# MCAN1_SS register map
Vendor: Texas Instruments
Peripheral module from a debugger description file (folder J7VCL).
Registers are 32-bit, read-only, reset 0x0 unless marked. A register's access mark holds for its fields unless they carry their own. Offsets are as the file gives them; lines under a group give offsets from that group; [hi:lo] are bit positions; {n}, {i} and the like mark numbered series; 'fields as' and 'values as' point back to an identical list; <NAME> marks a mode.

## MCAN1_SS
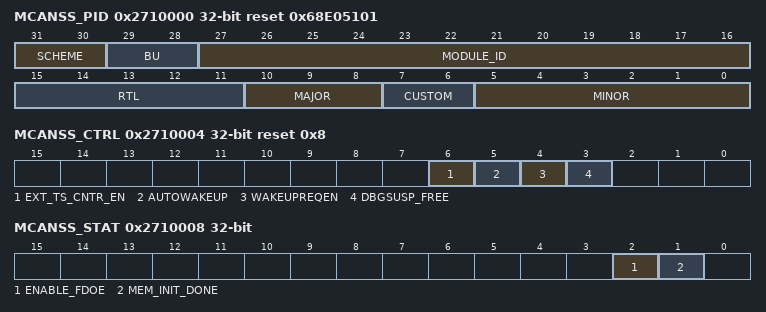
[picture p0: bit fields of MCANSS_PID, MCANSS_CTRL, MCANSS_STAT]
0x2710000 MCANSS_PID reset 0x68E05101 — Revision Register The Revision Register contains the major and minor revisions for the MCANSS.
  [31:30] SCHEME
  [29:28] BU — Business Unit (2h = Processors)
  [27:16] MODULE_ID
  [15:11] RTL — RTL Revision
  [10:8] MAJOR — Major Revision
  [7:6] CUSTOM
  [5:0] MINOR — Minor Revision
0x2710004 MCANSS_CTRL access per field reset 0x8 — Control Register The Control Register contains general control bits for the MCANSS.
  [6] EXT_TS_CNTR_EN rw — External Timestamp Counter Enable
  [5] AUTOWAKEUP rw — Automatic Wakeup Enable
  [4] WAKEUPREQEN rw — Wakeup Request Enable
  [3] DBGSUSP_FREE rw — Debug Suspend 0h = Honor debug suspend 1h = Disregard debug suspend
0x2710008 MCANSS_STAT (reset mask 0xFFFFFFFB) — Status Register The Status Register provides general status bits for the MCANSS.
  [2] ENABLE_FDOE — Enable FD (Flexible Data-Rate) Configuration Reflects the value of mcanss_enable_fdoe configuration port, -h = mcanss_enable_fdoe.
  [1] MEM_INIT_DONE — Memory Initialization 0h = Memory initialization is in progress 1h = Memory intialization done
0x271000C MCANSS_ICS access per field — Interrupt Clear Shadow Register Write 1h to clear interrupt bits.
  [0] EXT_TS_CNTR_OVFL wo — External Timestamp Counter Overflow Interrupt Status Write 1h to clear bits.
0x2710010 MCANSS_IRS access not given — Interrupt Raw Status Register Write 1h to set interrupt bits.
  [0] EXT_TS_CNTR_OVFL — External Timestamp Counter Overflow Interrupt Status Write 1h to set bits. (access RW1S)
0x2710014 MCANSS_IECS access not given — Interrupt Enable Clear Shadow Register Write 1h to clear interrupt enable bits.
  [0] EXT_TS_CNTR_OVFL — External Timestamp Counter Overflow Interrupt Write 1h to clear bits. (access W1C)
0x2710018 MCANSS_IE access not given — Interrupt Enable Register Write 1h to set interrupt bits.
  [0] EXT_TS_CNTR_OVFL — External Timestamp Counter Overflow Interrupt Write 1h to set bits. (access RW1S)
0x271001C MCANSS_IES — Interrupt Enable Status Register Read enabled interrupts.
  [0] EXT_TS_CNTR_OVFL — External Timestamp Counter Overflow Interrupt
0x2710020 MCANSS_EOI access per field — End Of Interrupt (EOI) Register The EOI register is used to re-trigger the pulse interrupt signal to ensure that any nested interrupt events are serviced. The software interrupt handler must write to the EOI register at the end of the current interrupt processing routine, so that new events can re-trigger the pulse interrupt signal again. For level interrupt signals the EOI register is not functional and must not be used.
  [7:0] EOI wo — End Of Interrupt Write with bit position of the targeted interrupt (example: external timestamp is bit 0). Upon write, level interrupt will clear and if unserviced interrupt counter &gt; 1h will issue another pulse interrupt. 0h = EOI value for external timestamp interrupt 1h = EOI value for mcan[0] interrupt 2h = EOI value for mcan[1] interrupt
0x2710024 MCANSS_EXT_TS_PRESCALER access per field — External Timestamp Prescaler Register
  [23:0] PRESCALER rw — External Timestamp Prescaler Reload Value External timestamp count rate is host clock rate divided by this value with one exception - a value of 0h has the same effect as 1h.
0x2710028 MCANSS_EXT_TS_UNSERVICED_INTR_CNTR — External Timestamp Unserviced Interrupts Counter Register
  [4:0] EXT_TS_INTR_CNTR — Number of Unserviced Rollover Interrupts If &gt; 1h an EOI write will issue another pulse interrupt.
